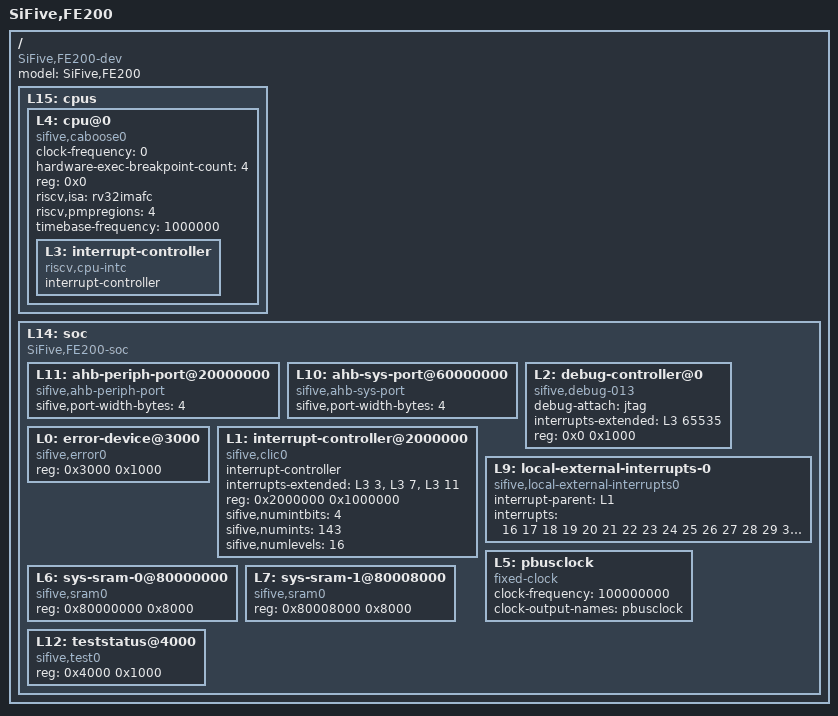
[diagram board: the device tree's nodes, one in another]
/dts-v1/;

/ {
	#address-cells = <1>;
	#size-cells = <1>;
	compatible = "SiFive,FE200-dev", "fe200-dev", "sifive-dev";
	model = "SiFive,FE200";
	L15: cpus {
		#address-cells = <1>;
		#size-cells = <0>;
		L4: cpu@0 {
			clock-frequency = <0>;
			compatible = "sifive,caboose0", "riscv";
			device_type = "cpu";
			hardware-exec-breakpoint-count = <4>;
			reg = <0x0>;
			riscv,isa = "rv32imafc";
			riscv,pmpregions = <4>;
			status = "okay";
			timebase-frequency = <1000000>;
			L3: interrupt-controller {
				#interrupt-cells = <1>;
				compatible = "riscv,cpu-intc";
				interrupt-controller;
			};
		};
	};
	L14: soc {
		#address-cells = <1>;
		#size-cells = <1>;
		compatible = "SiFive,FE200-soc", "fe200-soc", "sifive-soc", "simple-bus";
		ranges;
		L11: ahb-periph-port@20000000 {
			#address-cells = <1>;
			#size-cells = <1>;
			compatible = "sifive,ahb-periph-port", "sifive,ahb-port", "sifive,periph-port", "simple-external-bus", "simple-bus";
			ranges = <0x20000000 0x20000000 0x20000000>;
			sifive,port-width-bytes = <4>;
		};
		L10: ahb-sys-port@60000000 {
			#address-cells = <1>;
			#size-cells = <1>;
			compatible = "sifive,ahb-sys-port", "sifive,ahb-port", "sifive,sys-port", "simple-external-bus", "simple-bus";
			ranges = <0x60000000 0x60000000 0x20000000>;
			sifive,port-width-bytes = <4>;
		};
		L2: debug-controller@0 {
			compatible = "sifive,debug-013", "riscv,debug-013";
			debug-attach = "jtag";
			interrupts-extended = <&L3 65535>;
			reg = <0x0 0x1000>;
			reg-names = "control";
		};
		L0: error-device@3000 {
			compatible = "sifive,error0";
			reg = <0x3000 0x1000>;
		};
		L1: interrupt-controller@2000000 {
			#interrupt-cells = <1>;
			compatible = "sifive,clic0";
			interrupt-controller;
			interrupts-extended = <&L3 3 &L3 7 &L3 11>;
			reg = <0x2000000 0x1000000>;
			reg-names = "control";
			sifive,numintbits = <4>;
			sifive,numints = <143>;
			sifive,numlevels = <16>;
		};
		L9: local-external-interrupts-0 {
			compatible = "sifive,local-external-interrupts0";
			interrupt-parent = <&L1>;
			interrupts = <16 17 18 19 20 21 22 23 24 25 26 27 28 29 30 31 32 33 34 35 36 37 38 39 40 41 42 43 44 45 46 47 48 49 50 51 52 53 54 55 56 57 58 59 60 61 62 63 64 65 66 67 68 69 70 71 72 73 74 75 76 77 78 79 80 81 82 83 84 85 86 87 88 89 90 91 92 93 94 95 96 97 98 99 100 101 102 103 104 105 106 107 108 109 110 111 112 113 114 115 116 117 118 119 120 121 122 123 124 125 126 127 128 129 130 131 132 133 134 135 136 137 138 139 140 141 142>;
		};
		L5: pbusclock {
			#clock-cells = <0>;
			clock-frequency = <100000000>;
			clock-output-names = "pbusclock";
			compatible = "fixed-clock";
		};
		L6: sys-sram-0@80000000 {
			compatible = "sifive,sram0";
			reg = <0x80000000 0x8000>;
			reg-names = "mem";
		};
		L7: sys-sram-1@80008000 {
			compatible = "sifive,sram0";
			reg = <0x80008000 0x8000>;
			reg-names = "mem";
		};
		L12: teststatus@4000 {
			compatible = "sifive,test0";
			reg = <0x4000 0x1000>;
			reg-names = "control";
		};
	};
};
